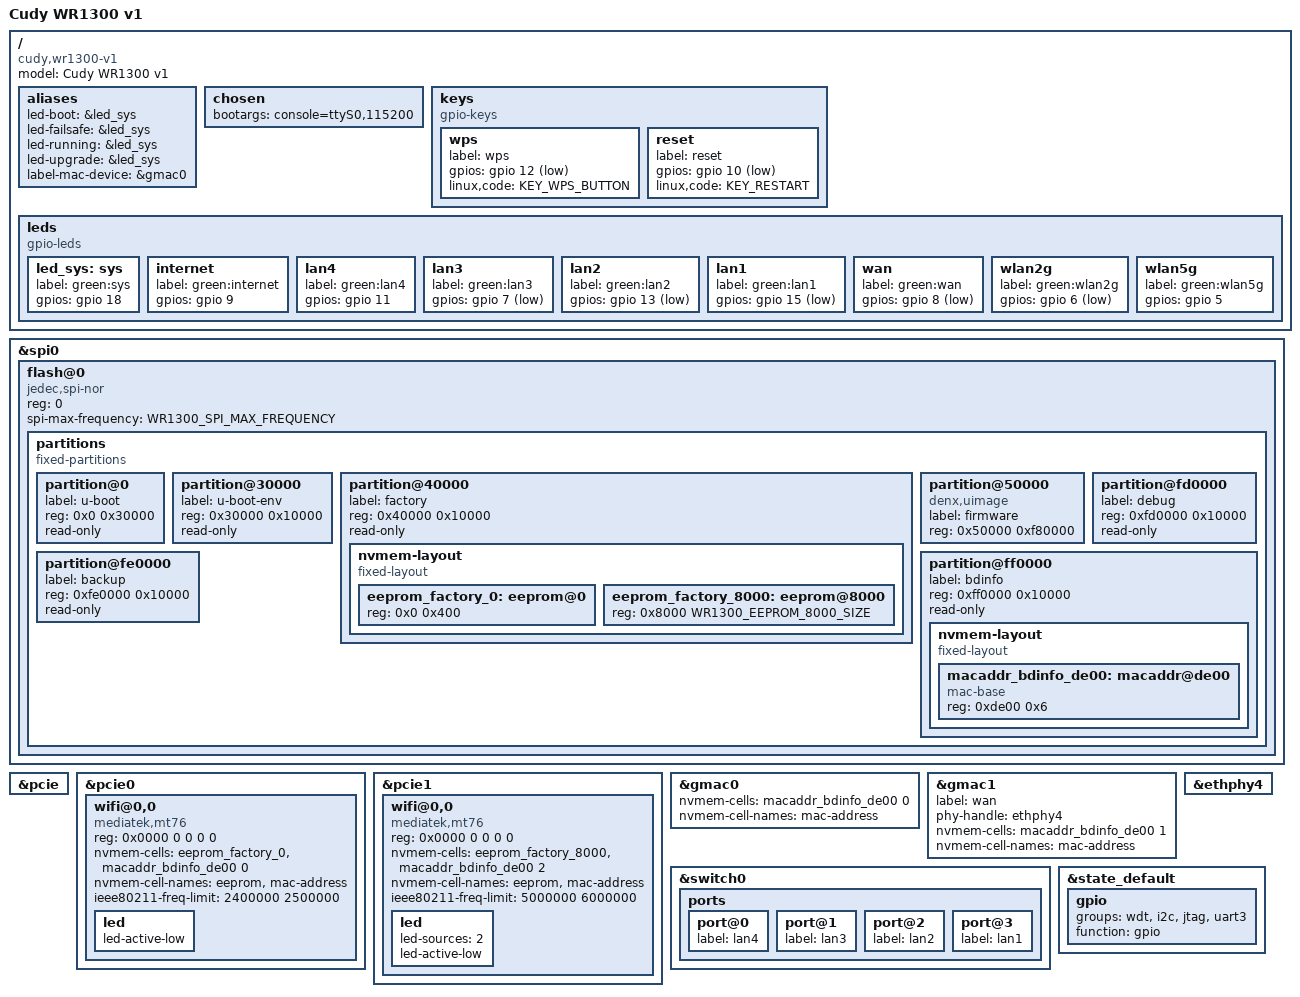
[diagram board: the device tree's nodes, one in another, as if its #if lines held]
// SPDX-License-Identifier: GPL-2.0-or-later OR MIT

#include "mt7621.dtsi"

#include <dt-bindings/gpio/gpio.h>
#include <dt-bindings/input/input.h>
#include <dt-bindings/leds/common.h>

#if defined(WR1300_V1)
#define WR1300_SPI_MAX_FREQUENCY	10000000
#define WR1300_EEPROM_8000_SIZE		0x200
#elif defined(WR1300_V2) || defined(WR1300_V3) || defined(WR1300_V4)
#define WR1300_SPI_MAX_FREQUENCY	40000000
#define WR1300_EEPROM_8000_SIZE		0x4da8
#else
#error "Unknown Cudy WR1300 hardware revision"
#endif

/ {
#if defined(WR1300_V1)
	compatible = "cudy,wr1300-v1", "mediatek,mt7621-soc";
	model = "Cudy WR1300 v1";
#elif defined(WR1300_V2)
	compatible = "cudy,wr1300-v2", "mediatek,mt7621-soc";
	model = "Cudy WR1300 v2";
#elif defined(WR1300_V3)
	compatible = "cudy,wr1300-v3", "mediatek,mt7621-soc";
	model = "Cudy WR1300 v3";
#elif defined(WR1300_V4)
	compatible = "cudy,wr1300-v4", "mediatek,mt7621-soc";
	model = "Cudy WR1300 v4";
#endif

	aliases {
		led-boot = &led_sys;
		led-failsafe = &led_sys;
		led-running = &led_sys;
		led-upgrade = &led_sys;
		label-mac-device = &gmac0;
	};

	chosen {
		bootargs = "console=ttyS0,115200";
	};

	keys {
		compatible = "gpio-keys";

#if defined(WR1300_V4)
		wps {
			label = "wps";
			gpios = <&gpio 12 GPIO_ACTIVE_LOW>;
			linux,code = <KEY_WPS_BUTTON>;
		};

		reset {
			label = "reset";
			gpios = <&gpio 10 GPIO_ACTIVE_LOW>;
			linux,code = <KEY_RESTART>;
		};
#elif defined(WR1300_V1)
		reset {
			label = "reset";
			gpios = <&gpio 18 GPIO_ACTIVE_LOW>;
			linux,code = <KEY_RESTART>;
		};

		wps {
			label = "wps";
			gpios = <&gpio 3 GPIO_ACTIVE_LOW>;
			linux,code = <KEY_WPS_BUTTON>;
		};
#else
		reset {
			label = "reset";
			gpios = <&gpio 18 GPIO_ACTIVE_LOW>;
			linux,code = <KEY_RESTART>;
		};

		wps {
			label = "wps";
			gpios = <&gpio 7 GPIO_ACTIVE_LOW>;
			linux,code = <KEY_WPS_BUTTON>;
		};
#endif
	};

	leds {
		compatible = "gpio-leds";

#if defined(WR1300_V4)
		led_sys: sys {
			label = "green:sys";
			gpios = <&gpio 18 GPIO_ACTIVE_HIGH>;
		};

		internet {
			label = "green:internet";
			gpios = <&gpio 9 GPIO_ACTIVE_HIGH>;
		};

		lan4 {
			label = "green:lan4";
			gpios = <&gpio 11 GPIO_ACTIVE_HIGH>;
		};

		lan3 {
			label = "green:lan3";
			gpios = <&gpio 7 GPIO_ACTIVE_LOW>;
		};

		lan2 {
			label = "green:lan2";
			gpios = <&gpio 13 GPIO_ACTIVE_LOW>;
		};

		lan1 {
			label = "green:lan1";
			gpios = <&gpio 15 GPIO_ACTIVE_LOW>;
		};

		wan {
			label = "green:wan";
			gpios = <&gpio 8 GPIO_ACTIVE_LOW>;
		};

		wlan2g {
			label = "green:wlan2g";
			gpios = <&gpio 6 GPIO_ACTIVE_LOW>;
		};

		wlan5g {
			label = "green:wlan5g";
			gpios = <&gpio 5 GPIO_ACTIVE_HIGH>;
		};
#elif defined(WR1300_V1)
		led_sys: sys {
			label = "green:sys";
			gpios = <&gpio 15 GPIO_ACTIVE_HIGH>;
		};

		usb {
			function = LED_FUNCTION_USB;
			color = <LED_COLOR_ID_GREEN>;
			gpios = <&gpio 14 GPIO_ACTIVE_HIGH>;
			trigger-sources = <&xhci_ehci_port1>, <&ehci_port2>;
			linux,default-trigger = "usbport";
		};

		wps {
			function = LED_FUNCTION_WPS;
			color = <LED_COLOR_ID_GREEN>;
			gpios = <&gpio 13 GPIO_ACTIVE_LOW>;
		};
#else
		led_sys: sys {
			label = "green:sys";
			gpios = <&gpio 15 GPIO_ACTIVE_LOW>;
		};

		wps {
			function = LED_FUNCTION_WPS;
			color = <LED_COLOR_ID_GREEN>;
			gpios = <&gpio 13 GPIO_ACTIVE_LOW>;
		};
#endif
	};
};

&spi0 {
	status = "okay";

	flash@0 {
		compatible = "jedec,spi-nor";
		reg = <0>;
		spi-max-frequency = <WR1300_SPI_MAX_FREQUENCY>;

		partitions {
			compatible = "fixed-partitions";
			#address-cells = <1>;
			#size-cells = <1>;

			partition@0 {
				label = "u-boot";
				reg = <0x0 0x30000>;
				read-only;
			};

			partition@30000 {
				label = "u-boot-env";
				reg = <0x30000 0x10000>;
				read-only;
			};

			partition@40000 {
				label = "factory";
				reg = <0x40000 0x10000>;
				read-only;

				nvmem-layout {
					compatible = "fixed-layout";
					#address-cells = <1>;
					#size-cells = <1>;

					eeprom_factory_0: eeprom@0 {
						reg = <0x0 0x400>;
					};

					eeprom_factory_8000: eeprom@8000 {
						reg = <0x8000 WR1300_EEPROM_8000_SIZE>;
					};
				};
			};

			partition@50000 {
				compatible = "denx,uimage";
				label = "firmware";
				reg = <0x50000 0xf80000>;
			};

			partition@fd0000 {
				label = "debug";
				reg = <0xfd0000 0x10000>;
				read-only;
			};

			partition@fe0000 {
				label = "backup";
				reg = <0xfe0000 0x10000>;
				read-only;
			};

			partition@ff0000 {
				label = "bdinfo";
				reg = <0xff0000 0x10000>;
				read-only;

				nvmem-layout {
					compatible = "fixed-layout";
					#address-cells = <1>;
					#size-cells = <1>;

					macaddr_bdinfo_de00: macaddr@de00 {
						compatible = "mac-base";
						reg = <0xde00 0x6>;
						#nvmem-cell-cells = <1>;
					};
				};
			};
		};
	};
};

&pcie {
	status = "okay";
};

#if defined(WR1300_V1)
&pcie0 {
	wifi@0,0 {
		compatible = "mediatek,mt76";
		reg = <0x0000 0 0 0 0>;
		nvmem-cells = <&eeprom_factory_0>, <&macaddr_bdinfo_de00 0>;
		nvmem-cell-names = "eeprom", "mac-address";
		ieee80211-freq-limit = <2400000 2500000>;

		led {
			led-active-low;
		};
	};
};

&pcie1 {
	wifi@0,0 {
		compatible = "mediatek,mt76";
		reg = <0x0000 0 0 0 0>;
		nvmem-cells = <&eeprom_factory_8000>, <&macaddr_bdinfo_de00 2>;
		nvmem-cell-names = "eeprom", "mac-address";
		ieee80211-freq-limit = <5000000 6000000>;

		led {
			led-sources = <2>;
			led-active-low;
		};
	};
};
#elif defined(WR1300_V2)
&pcie1 {
	wifi@0,0 {
		compatible = "mediatek,mt76";
		reg = <0x0000 0 0 0 0>;
		nvmem-cells = <&eeprom_factory_0>, <&macaddr_bdinfo_de00 0>;
		nvmem-cell-names = "eeprom", "mac-address";
		ieee80211-freq-limit = <2400000 2500000>;
	};
};

&pcie0 {
	wifi@0,0 {
		compatible = "mediatek,mt76";
		reg = <0x0000 0 0 0 0>;
		nvmem-cells = <&eeprom_factory_8000>, <&macaddr_bdinfo_de00 2>;
		nvmem-cell-names = "eeprom", "mac-address";
		ieee80211-freq-limit = <5000000 6000000>;
	};
};
#elif defined(WR1300_V3)
&pcie0 {
	wifi@0,0 {
		compatible = "mediatek,mt76";
		reg = <0x0000 0 0 0 0>;
		nvmem-cells = <&eeprom_factory_0>, <&macaddr_bdinfo_de00 0>;
		nvmem-cell-names = "eeprom", "mac-address";
		ieee80211-freq-limit = <2400000 2500000>;

		led {
			led-sources = <0>;
			led-active-low;
		};
	};
};

&pcie1 {
	wifi@0,0 {
		compatible = "mediatek,mt76";
		reg = <0x0000 0 0 0 0>;
		nvmem-cells = <&eeprom_factory_8000>, <&macaddr_bdinfo_de00 2>;
		nvmem-cell-names = "eeprom", "mac-address";
		ieee80211-freq-limit = <5000000 6000000>;
	};
};
#elif defined(WR1300_V4)
&pcie0 {
	wifi@0,0 {
		compatible = "mediatek,mt76";
		reg = <0x0000 0 0 0 0>;
		nvmem-cells = <&eeprom_factory_0>, <&macaddr_bdinfo_de00 0>;
		nvmem-cell-names = "eeprom", "mac-address";
		ieee80211-freq-limit = <2400000 2500000>;
	};
};

&pcie1 {
	wifi@0,0 {
		compatible = "mediatek,mt76";
		reg = <0x0000 0 0 0 0>;
		nvmem-cells = <&eeprom_factory_8000>, <&macaddr_bdinfo_de00 2>;
		nvmem-cell-names = "eeprom", "mac-address";
		ieee80211-freq-limit = <5000000 6000000>;
	};
};
#endif

&gmac0 {
	nvmem-cells = <&macaddr_bdinfo_de00 0>;
	nvmem-cell-names = "mac-address";
};

&gmac1 {
	status = "okay";
	label = "wan";
	phy-handle = <&ethphy4>;
	nvmem-cells = <&macaddr_bdinfo_de00 1>;
	nvmem-cell-names = "mac-address";
};

&ethphy4 {
	/delete-property/ interrupts;
};

&switch0 {
	ports {
		port@0 {
			status = "okay";
			label = "lan4";
		};

		port@1 {
			status = "okay";
			label = "lan3";
		};

		port@2 {
			status = "okay";
			label = "lan2";
		};

		port@3 {
			status = "okay";
			label = "lan1";
		};
	};
};

&state_default {
	gpio {
#if defined(WR1300_V4)
		groups = "wdt", "i2c", "jtag", "uart3";
#else
		groups = "wdt", "i2c", "jtag";
#endif
		function = "gpio";
	};
};
